# osprey_dcache_secure register map
Vendor: Texas Instruments
Peripheral module from a debugger description file (folder CC35X1E).
Registers are 32-bit, access per field, reset values left out (the file's numbers can be read two ways) unless marked. A register's access mark holds for its fields unless they carry their own. Offsets are as the file gives them; lines under a group give offsets from that group; [hi:lo] are bit positions; {n}, {i} and the like mark numbered series; 'fields as' and 'values as' point back to an identical list; <NAME> marks a mode.

## osprey_dcache_secure
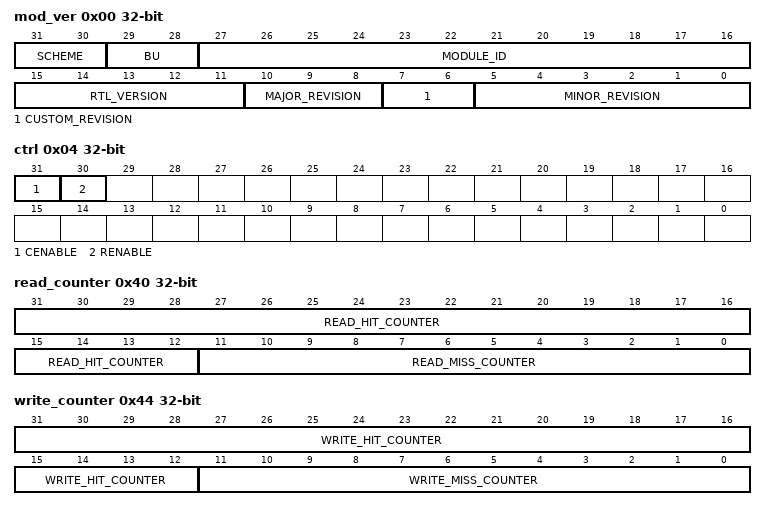
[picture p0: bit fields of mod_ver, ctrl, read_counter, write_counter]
0x00 mod_ver ro — The Module and Version Register identifies the module identifier and revision of the L1 module.
  [31:30] SCHEME — Module Scheme
  [29:28] BU — Module Business Unit
  [27:16] MODULE_ID — L1 module ID.
  [15:11] RTL_VERSION
  [10:8] MAJOR_REVISION
  [7:6] CUSTOM_REVISION
  [5:0] MINOR_REVISION
0x04 ctrl — The control register defines the size of the remote cache data storage memory to use and whether the L1 is enabled.
  [31] CENABLE rw — The ~icenable field determines whether the L1 configuration is enabled or not.#br# 0: Disabled#br# 1: Enabled #br# This field is write protected when the t_cfg_lock_ipcfg input is high.
  [30] RENABLE rw — The ~irenable field determines if half the cache space is RAM or cache. #br# 0: No RAM 64K of cache#br# 1: RAM 32K of cache, 32K of RAM. This field is write protected when ~icenable is set or the t_cfg_lock_ipcfg input is high.
0x08 sts ro — The Status register displays the state of the L1 module
  [31] OK_TO_GO — The ~iok_to_go status bit indicates the Tag/LRU Ram has been initialized and the cache is in an operable state.
0x10 cal — The L1 Cache Address Low Register defines start of the L1 cacheable space. The L1 cache can cache up to a range of 8MB of of the target Flash as defined by CAL>=CachedRange<=CAH. This register is write protected when ~icenable is set or the t_cfg_lock_ipcfg input is high.
  [31:12] ADDR_LO rw — The ~iaddr_lo defines the L1 low address[31:12] for the L1 to cache. The remaining bits 10:0 are assumed to be zero.
0x18 cah — The L1 Cache Address High Register defines end of the L1 cacheable space. The L1 cache can cache up to a range of 8MB of of the target Flash as defined by CAL>=CachedRange<=CAH. This register is write protected when ~icenable is set or the t_cfg_lock_ipcfg input is high.
  [31:12] ADDR_HI rw — The ~iaddr_hi defines the L1 high address[31:12] for the L1 to cache. The remaining bits 10:0 are assumed to be ones.
0x40 read_counter rw — The L1 HIT Counter register holds the number of L1 Hits to the internal cache.
  [31:12] READ_HIT_COUNTER — The hit Counts the number of hits to the L1 cache. Writing zero to this register will clear its contents When one reach the max, the rest of the counters are halted too.
  [11:0] READ_MISS_COUNTER — The miss Counts the number of misses to the L1 cache. Writing zero to this register will clear its contents. When one reach the max, the rest of the counters are halted too.
0x44 write_counter rw — The L1 MISS Counter register holds the number of L1 Misses to the internal cache.
  [31:12] WRITE_HIT_COUNTER — The hit Counts the number of hits to the L1 cache. Writing zero to this register will clear its contents. When one reach the max, the rest of the counters are halted too.
  [11:0] WRITE_MISS_COUNTER — The miss Counts the number of misses to the L1 cache. Writing zero to this register will clear its contents. When one reach the max, the rest of the counters are halted too
0x48 address_latch rw — When having OTFDE AHB error, Latch the address accessed by D-cache
  [31:0] ADDRESS_LATCH — When D-cache receive AHB error from the OTFDE it should latch the address accessed by D-cache. (OTFDE generates an error for write only) Writing zero to this register will clear its contents.
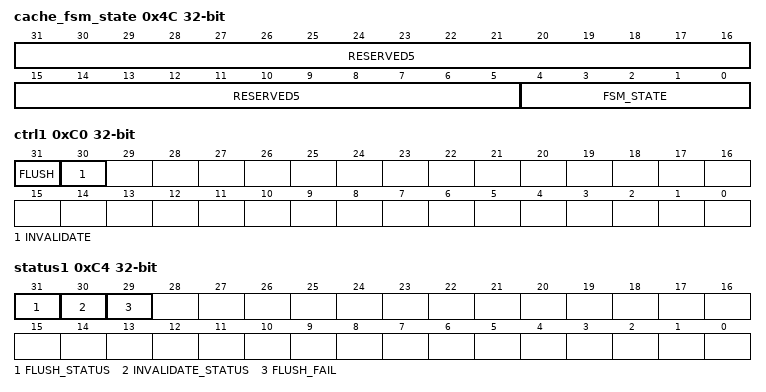
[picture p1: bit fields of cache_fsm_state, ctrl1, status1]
0x4C cache_fsm_state ro
  [31:5] RESERVED5 — Dcache current FSM state
  [4:0] FSM_STATE — Dcache current FSM state WIDLE = 5'd0; - No access to D-cache WRAMWR = 5'd1; - Data RAM Write WRAMRD = 5'd2; - Data RAM Read WCREADT = 5'd4; - Read Hit WCREADC = 5'd5; - Read Miss WCWRITET = 5'd6; - Write Hit EVICT = 5'd7; -Write back to PSRAM WR_ALLOC = 5'd8; - Write Allocate in write miss RD_WA = 5'd9; - Word aligned read for a byte aligned read WD = 5'd10; - Writing data to PSRAM RDATA_CACHE = 5'd3; Reading data RAM for eviction DEC_DIR = 5'd11; - Deciding direction RDATA_CACHE_FLUSH = 5'd12; Reading data from data RAM for flush RD_SET = 5'd13; Reading TAG & MRU DET_GRANT = 5'd14; Detecting the granted way to evict EVICT_FLUSH = 5'd15; Eviction during Flush WD_DEBUG = 5'd16; Writing data to PSRAM during a debugger access
0x80 irqstatus_raw — The Interrupt Raw Status Register holds the raw status of the L1 error interrupts. Note: Read to the field of this register gives raw status of corresponding interrupt. S/W can set corresponding interrupt field for diagnostic purposes.
  [1] LOCK_CFG_WR rw — The ~ilock_cfg_wr bit indicates a write to a locked configuration register has occured. Write 1 to set the ~ilock_cfg_wr status for diagnostic purposes. Writing a 0 has no effect.
0x84 irqstatus_msk — The Interrupt Masked Status Register holds the masked status for the L1 error interrupts. Writing to this register will EOI the interrupt, that is if another interrupt is pending, a new pulse interrupt will be generated. Note: Read to the field of this register gives masked status of corresponding interrupt. Writing 1 to the field of this register clears corresponding interrupt.
  [1] LOCK_CFG_WR rw — The ~ilock_cfg_wr bit indicates a write to a locked configuration register has occured. Write 1 to clear the ~ilock_cfg_wr status after interrupt has been serviced (raw status gets cleared, i.e. even if not enabled). Writing a 0 has no effect to this field.
0x88 irqenable_set — The Interrupt Enable Set Register holds the interrupt enable status of the L1 error interrupts. Note:Writing 1 to field of this register will not mask the corresponding interrupt. IRQSTATUS_RAW and IRQSTATUS_MSK status field gives the same status.
  [1] EN_LOCK_CFG_WR rw — Interrupt Enable Set for ~ilock_cfg_wr error bit. Writing a 1 will enable the interrupt, and set this bit as well as the corresponding Interrupt Enable Clear Register. Writing a 0 has no effect.
0x8C irqenable_clr — The Interrupt Enable Clear Register holds the interrupt enable status of the L1 error interrupts. Note:Writing 1 to field of this register masks the corresponding interrupt. IRQSTATUS_RAW and IRQSTATUS_MSK status field gives the raw status and masked status respectively
  [1] EN_LOCK_CFG_WR rw — Interrupt Enable Clear for ~ilock_cfg_wr error bit. Writing a 1 will disable the interrupt, and clear this bit as well as the corresponding Interrupt Enable Set Register. Writing a 0 has no effect.
0xC0 ctrl1 — Flush and invalidates requests
  [31] FLUSH rw — 0x0 - Do nothing 0x1 - Flush The bit is self cleared when flush completed
  [30] INVALIDATE rw — 0x0 - Do nothing 0x1 - Invalidate This bit is self cleared when invalidate completed
0xC4 status1 ro — Flush and invalidates status
  [31] FLUSH_STATUS — This bit indicates that Flush as been completed ( Bit is cleared when Flush request bit is asserted )
  [30] INVALIDATE_STATUS — This bit indicates that invalidate has been completed ( Bit is cleared when flush request bit is asserted )
  [29] FLUSH_FAIL — This bit indicates that Flush has failed ( Bit is cleared when Flush request bit is asserted )
